# M451_v1 register map
File version: 1.0
Registers are 32-bit, read-write, reset 0x0 unless marked. A register's access mark holds for its fields unless they carry their own. Offsets are from the block's base; [hi:lo] are bit positions; {n}, {i} and the like mark numbered series.

## RTC — RTC Register Map
Base 0x40041000
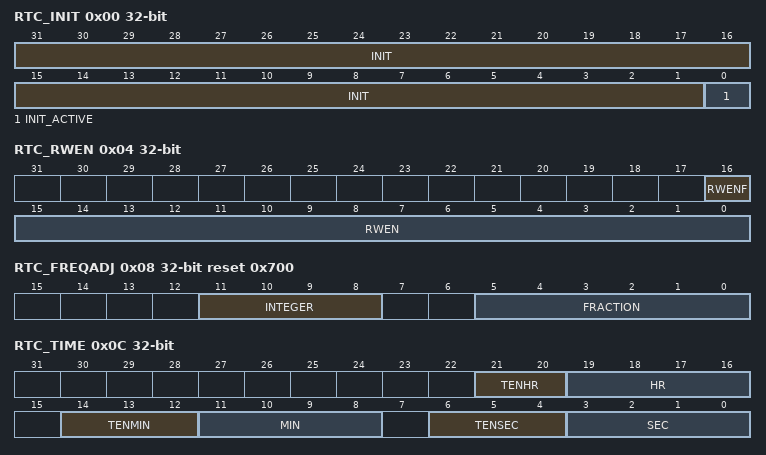
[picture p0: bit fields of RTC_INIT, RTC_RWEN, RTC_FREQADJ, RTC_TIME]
0x00 RTC_INIT — RTC Initiation Register
  [31:1] INIT — RTC Initiation. When RTC block is powered on, RTC is at reset state. User has to write a number (0x a5eb1357) to INIT to make RTC leaving reset state. Once the INIT is written as 0xa5eb1357, the RTC will be in un-reset state permanently. The INIT is a write-only field and read value will be always 0.
  [0] INIT_ACTIVE ro — RTC Active Status (Read Only)
    0=RTC is at reset state; 1=RTC is at normal active state
0x04 RTC_RWEN — RTC Access Enable Register
  [16] RWENF ro — RTC Register Access Enable Flag (Read Only). This bit will be set after RTC_RWEN[15:0] register is load a 0xA965, and be cleared automatically after 1024 RTC clock.
    0=RTC register read/write Disabled; 1=RTC register read/write Enabled
  [15:0] RWEN wo — RTC Register Access Enable Password (Write Only). Writing 0xA965 to this register will enable RTC access and keep 1024 RTC clock.
0x08 RTC_FREQADJ reset 0x700 — RTC Frequency Compensation Register
  [11:8] INTEGER — Integer Part
  [5:0] FRACTION — Fraction Part. Note: Digit in RTC_FREQADJ must be expressed as hexadecimal number.
0x0C RTC_TIME — RTC Time Loading Register
  [21:20] TENHR — 10-hour Time Digit (0~2). When RTC runs as 12-hour time scale mode, RTC_TIME[21] (the high bit of TENHR[1:0]) means AM/PM indication. (If RTC_TIME[21] is 1, it indicates PM time message.)
  [19:16] HR — 1-Hour Time Digit (0~9)
  [14:12] TENMIN — 10-Min Time Digit (0~5)
  [11:8] MIN — 1-Min Time Digit (0~9)
  [6:4] TENSEC — 10-Sec Time Digit (0~5)
  [3:0] SEC — 1-Sec Time Digit (0~9)
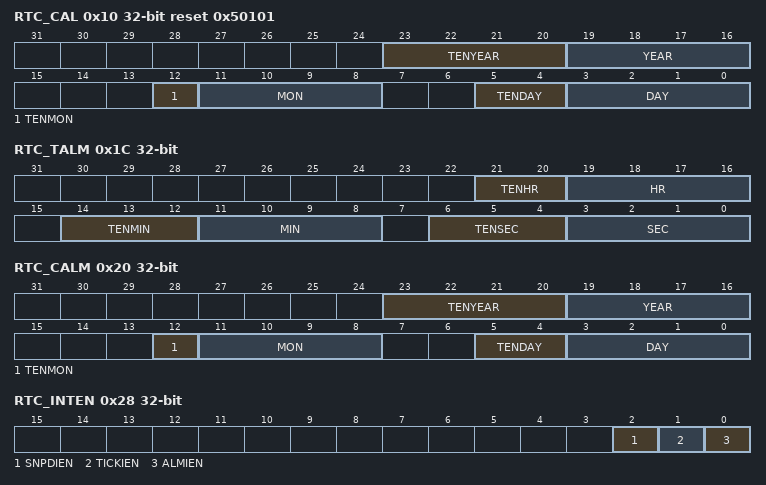
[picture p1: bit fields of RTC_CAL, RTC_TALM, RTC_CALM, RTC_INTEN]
0x10 RTC_CAL reset 0x50101 — RTC Calendar Loading Register
  [23:20] TENYEAR — 10-Year Calendar Digit (0~9)
  [19:16] YEAR — 1-Year Calendar Digit (0~9)
  [12] TENMON — 10-Month Calendar Digit (0~1)
  [11:8] MON — 1-Month Calendar Digit (0~9)
  [5:4] TENDAY — 10-Day Calendar Digit (0~3)
  [3:0] DAY — 1-Day Calendar Digit (0~9)
0x14 RTC_CLKFMT reset 0x1 — RTC Time Scale Selection Register
  [0] _24HEN — 24-hour / 12-hour Time Scale Selection. Indicates that RTC_TIME and RTC_TALM are in 24-hour time scale or 12-hour time scale
    0=12-hour time scale with AM and PM indication selected; 1=24-hour time scale selected
0x18 RTC_WEEKDAY reset 0x6 — RTC Day of the Week Register
  [2:0] WEEKDAY — Day of the Week Register
    0=Sunday; 1=Monday; 2=Tuesday; 3=Wednesday; 4=Thursday; 5=Friday; 6=Saturday
0x1C RTC_TALM — RTC Time Alarm Register
  [21:20] TENHR — 10-hour Time Digit of Alarm Setting (0~2). When RTC runs as 12-hour time scale mode, the high bit of TENHR (RTC_TIME[21]) means AM/PM indication.
  [19:16] HR — 1-Hour Time Digit of Alarm Setting (0~9)
  [14:12] TENMIN — 10-Min Time Digit of Alarm Setting (0~5)
  [11:8] MIN — 1-Min Time Digit of Alarm Setting (0~9)
  [6:4] TENSEC — 10-Sec Time Digit of Alarm Setting (0~5)
  [3:0] SEC — 1-Sec Time Digit of Alarm Setting (0~9)
0x20 RTC_CALM — RTC Calendar Alarm Register
  [23:20] TENYEAR — 10-Year Calendar Digit of Alarm Setting (0~9)
  [19:16] YEAR — 1-Year Calendar Digit of Alarm Setting (0~9)
  [12] TENMON — 10-Month Calendar Digit of Alarm Setting (0~1)
  [11:8] MON — 1-Month Calendar Digit of Alarm Setting (0~9)
  [5:4] TENDAY — 10-Day Calendar Digit of Alarm Setting (0~3)
  [3:0] DAY — 1-Day Calendar Digit of Alarm Setting (0~9)
0x24 RTC_LEAPYEAR ro — RTC Leap Year Indicator Register
  [0] LEAPYEAR — Leap Year Indication Register (Read Only)
    0=This year is not a leap year; 1=This year is leap year
0x28 RTC_INTEN — RTC Interrupt Enable Register
  [2] SNPDIEN — Snoop Detection Interrupt Enable Bit
    0=Snoop detected interrupt Disabled; 1=Snoop detected interrupt Enabled
  [1] TICKIEN — Time Tick Interrupt Enable Bit
    0=RTC Time Tick interrupt Disabled; 1=RTC Time Tick interrupt Enabled
  [0] ALMIEN — Alarm Interrupt Enable Bit
    0=RTC Alarm interrupt Disabled; 1=RTC Alarm interrupt Enabled
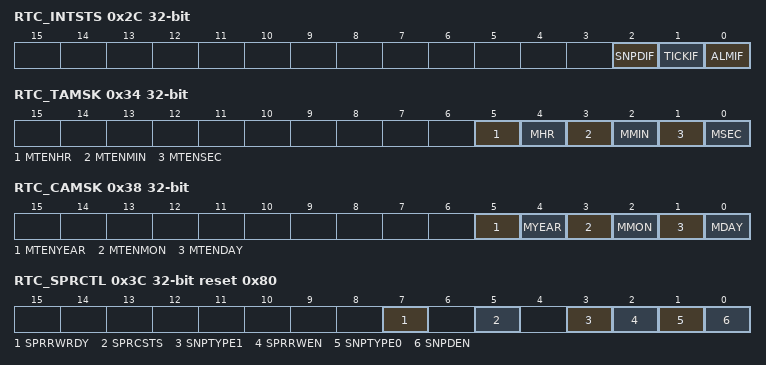
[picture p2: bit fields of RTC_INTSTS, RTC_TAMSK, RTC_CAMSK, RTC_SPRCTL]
0x2C RTC_INTSTS — RTC Interrupt Indicator Register
  [2] SNPDIF — Snoop Detect Interrupt Flag. When tamper pin transition event is detected, this bit is set to 1 and an interrupt is generated if Snoop Detection Interrupt enabled SNPDIEN (RTC_INTEN[2]) is set to1. Chip will be waken up from Power-down mode if spare register snooper detect interrupt is enabled. Note: Write 1 to clear this bit.
    0=No snoop event is detected; 1=Snoop event is detected
  [1] TICKIF — RTC Time Tick Interrupt Flag. When RTC time tick happened, this bit will be set to 1 and an interrupt will be generated if RTC Tick Interrupt enabled TICKIEN (RTC_INTEN[1]) is set to 1. Chip will also be waken up if RTC Tick Interrupt is enabled and this bit is set to 1 when chip is running at Power-down mode. Note: Write 1 to clear to clear this bit.
    0=Tick condition does not occur; 1=Tick condition occur
  [0] ALMIF — RTC Alarm Interrupt Flag. When RTC time counters RTC_TIME and RTC_CAL match the alarm setting time registers RTC_TALM and RTC_CALM, this bit will be set to 1 and an interrupt will be generated if RTC Alarm Interrupt enabled ALMIEN (RTC_INTEN[0]) is set to 1. Chip will be waken up if RTC Alarm Interrupt is enabled when chip is at Power-down mode. Note: Write 1 to clear this bit.
    0=Alarm condition is not matched; 1=Alarm condition is matched
0x30 RTC_TICK — RTC Time Tick Register
  [2:0] TICK — Time Tick Register. These bits are used to select RTC time tick period for Periodic Time Tick Interrupt request. Note: This register can be read back after the RTC register access enable bit RWENF (RTC_RWEN[16]) is active.
    0=Time tick is 1 second; 1=Time tick is 1/2 second; 2=Time tick is 1/4 second; 3=Time tick is 1/8 second; 4=Time tick is 1/16 second; 5=Time tick is 1/32 second; 6=Time tick is 1/64 second; 7=Time tick is 1/28 second
0x34 RTC_TAMSK — RTC Time Alarm Mask Register
  [5] MTENHR — Mask 10-Hour Time Digit of Alarm Setting (0~2)
  [4] MHR — Mask 1-Hour Time Digit of Alarm Setting (0~9)
  [3] MTENMIN — Mask 10-Min Time Digit of Alarm Setting (0~5)
  [2] MMIN — Mask 1-Min Time Digit of Alarm Setting (0~9)
  [1] MTENSEC — Mask 10-Sec Time Digit of Alarm Setting (0~5)
  [0] MSEC — Mask 1-Sec Time Digit of Alarm Setting (0~9)
0x38 RTC_CAMSK — RTC Calendar Alarm Mask Register
  [5] MTENYEAR — Mask 10-Year Calendar Digit of Alarm Setting (0~9)
  [4] MYEAR — Mask 1-Year Calendar Digit of Alarm Setting (0~9)
  [3] MTENMON — Mask 10-Month Calendar Digit of Alarm Setting (0~1)
  [2] MMON — Mask 1-Month Calendar Digit of Alarm Setting (0~9)
  [1] MTENDAY — Mask 10-Day Calendar Digit of Alarm Setting (0~3)
  [0] MDAY — Mask 1-Day Calendar Digit of Alarm Setting (0~9)
0x3C RTC_SPRCTL reset 0x80 — RTC Spare Functional Control Register
  [7] SPRRWRDY — SPR Register Ready. This bit indicates if the registers RTC_SPRCTL, RTC_SPR0 ~ RTC_SPR19 are ready to be accessed. After user writing registers RTC_SPRCTL, RTC_SPR0 ~ RTC_SPR19, read this bit to check if these registers are updated done is necessary. Note: This bit is read only and any write to it won't take any effect.
    0=RTC_SPRCTL, RTC_SPR0 ~ RTC_SPR19 updating is in progress; 1=RTC_SPRCTL, RTC_SPR0 ~ RTC_SPR19 are updated done and ready to be accessed
  [5] SPRCSTS — SPR Clear Flag. This bit indicates if the RTC_SPR0 ~RTC_SPR19 content is cleared when specify snoop event is detected. Writes 1 to clear this bit.
    0=Spare register content is not cleared; 1=Spare register content is cleared
  [3] SNPTYPE1 — Snoop Detection Mode. This bit controls TAMPER pin is edge or level detection
    0=Level detection; 1=Edge detection
  [2] SPRRWEN — Spare Register Enable Bit. Note: When spare register is disabled, RTC_SPR0 ~ RTC_SPR19 cannot be accessed.
    0=Spare register is Disabled; 1=Spare register is Enabled
  [1] SNPTYPE0 — Snoop Detection Level. This bit controls TAMPER detect event is high level/rising edge or low level/falling edge.
    0=Low level/Falling edge detection; 1=High level/Rising edge detection
  [0] SNPDEN — Snoop Detection Enable Bit
    0=TAMPER pin detection is Disabled; 1=TAMPER pin detection is Enabled
{0x40+4i} RTC_SPR{i} (i=0..19) — RTC Spare Register {i}
  [31:0] SPARE — Spare Register. This field is used to store back-up information defined by user. This field will be cleared by hardware automatically once a snooper pin event is detected. Before storing back-up information in to RTC_SPRx register, user should write 0xA965 to RTC_RWEN[15:0] to make sure register read/write enable bit REWNF (RTC_RWEN[16]) is enabled.
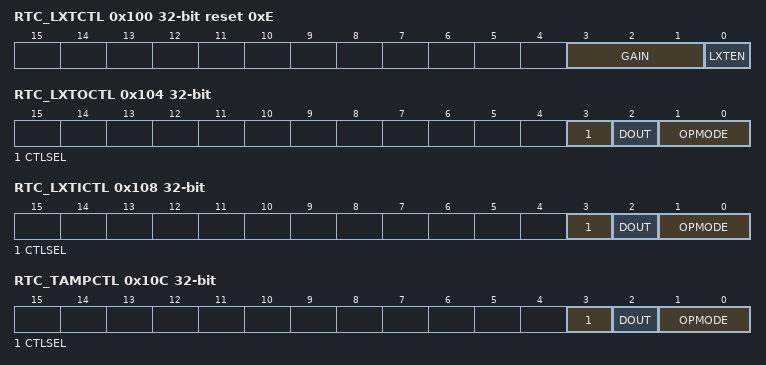
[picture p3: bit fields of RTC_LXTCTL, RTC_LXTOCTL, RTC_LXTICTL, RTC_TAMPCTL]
0x100 RTC_LXTCTL reset 0xE — RTC 32.768 KHz Oscillator Control Register
  [3:1] GAIN — Oscillator Gain Option. User can select oscillator gain according to crystal external loading and operating temperature range. The larger gain value corresponding to stronger driving capability and higher power consumption.
    {v}=L{v} mode (v=0..6); 7=L7 mode (Default)
  [0] LXTEN — Backup Domain 32K Oscillator Enable Bit. This bit controls 32 kHz oscillator on/off. User can set either LXTEN in RTC battery power domain or system manager control register CLK_PWRCTL[1] (LXTEN) to enable 32 kHz oscillator. If this bit is set 1, X32 kHz oscillator keep running after system core power is turned off, if this bit is clear to 0, oscillator is turned off when system core power is turned off.
    0=Oscillator is Disabled; 1=Oscillator is Enabled
0x104 RTC_LXTOCTL — X32KO Pin Control Register
  [3] CTLSEL — IO Pin State Backup Selection. When low speed 32 kHz oscillator is disabled, X32KO (PF.0) pin can be used as GPIO function. User can program CTLSEL bit to decide X32KO (PF.0) I/O function is controlled by system power domain GPIO module or VBAT power domain RTC_LXTOCTL control register.
    0=X32KO (PF.0) pin I/O function is controlled by GPIO module. It becomes floating when system power is turned off; 1=X32KO (PF.0) pin I/O function is controlled by VBAT power domain, X32KO (PF.0) pin function and I/O status are controlled by OPMODE[1:0] and DOUT after CTLSEL it set to 1. I/O pin keeps the previous state after system power is turned off
  [2] DOUT — IO Output Data
    0=X32KO (PF.0) output low; 1=X32KO (PF.0) output high
  [1:0] OPMODE — GPF0 Operation Mode
    0=X32KO (PF.0) is input only mode, without pull-up resistor; 1=X32KO (PF.0) is output push pull mode; 2=X32KO (PF.0) is open drain mode; 3=X32KO (PF.0) is input only mode with internal pull up
0x108 RTC_LXTICTL — X32KI Pin Control Register
  [3] CTLSEL — IO Pin State Backup Selection. When low speed 32 kHz oscillator is disabled, X32KI (PF.1) pin can be used as GPIO function. User can program CTLSEL bit to decide X32KI (PF.1) I/O function is controlled by system power domain GPIO module or VBAT power domain RTC_LXTICTL control register.
    0=X32KI (PF.1) pin I/O function is controlled by GPIO module. It becomes floating state when system power is turned off; 1=X32KI (PF.1) pin I/O function is controlled by VBAT power domain, X32KI (PF.1) pin function and I/O status are controlled by OPMODE[1:0] and DOUT after CTLSEL it set to 1. I/O pin keeps the previous state after system power is turned off
  [2] DOUT — IO Output Data
    0=X32KI (PF.1) output low; 1=X32KI (PF.1) output high
  [1:0] OPMODE — IO Operation Mode
    0=X32KI (PF.1) is input only mode, without pull-up resistor; 1=X32KI (PF.1) is output push pull mode; 2=X32KI (PF.1) is open drain mode; 3=X32KI (PF.1) is input only mode with internal pull up
0x10C RTC_TAMPCTL — TAMPER Pin Control Register
  [3] CTLSEL — IO Pin State Backup Selection. When tamper function is disabled, TAMPER pin can be used as GPIO function. User can program CTLSEL bit to decide PF.2 I/O function is controlled by system power domain GPIO module or VBAT power domain RTC_TAMPCTL control register.
    0=TAMPER (PF.2) I/O function is controlled by GPIO module. It becomes floating state when system power is turned off; 1=TAMPER (PF.2) I/O function is controlled by VBAT power domain. PF.2 function and I/O status are controlled by OPMODE[1:0] and DOUT after CTLSEL it set to 1. I/O pin state keeps previous state after system power is turned off
  [2] DOUT — IO Output Data
    0=TAMPER (PF.2) output low; 1=TAMPER (PF.2) output high
  [1:0] OPMODE — IO Operation Mode
    0=TAMPER (PF.2) is input only mode, without pull-up resistor; 1=TAMPER (PF.2) is output push pull mode; 2=TAMPER (PF.2) is open drain mode; 3=TAMPER (PF.2) is input only mode with internal pull up
